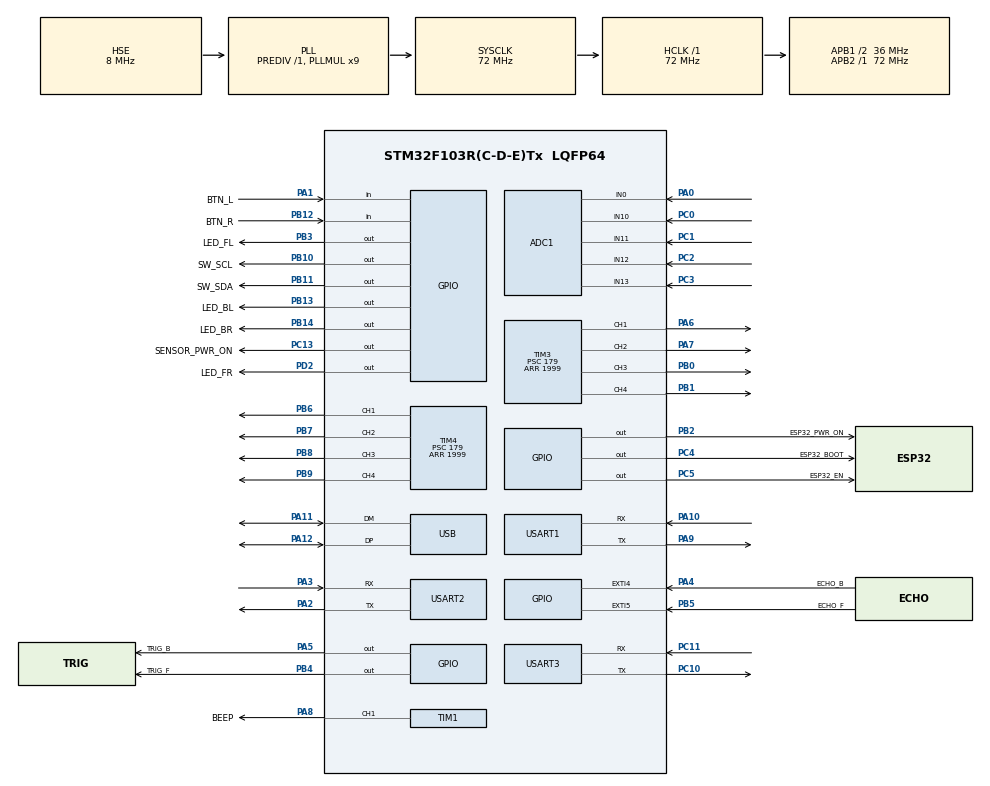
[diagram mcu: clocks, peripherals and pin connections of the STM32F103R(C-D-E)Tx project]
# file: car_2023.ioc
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ADC1.Channel-0\#ChannelRegularConversion=ADC_CHANNEL_10
ADC1.Channel-1\#ChannelRegularConversion=ADC_CHANNEL_11
ADC1.Channel-2\#ChannelRegularConversion=ADC_CHANNEL_12
ADC1.Channel-3\#ChannelRegularConversion=ADC_CHANNEL_13
ADC1.Channel-4\#ChannelRegularConversion=ADC_CHANNEL_0
ADC1.NbrOfConversion=5
ADC1.NbrOfConversionFlag=1
ADC1.Rank-0\#ChannelRegularConversion=1
ADC1.Rank-1\#ChannelRegularConversion=2
ADC1.Rank-2\#ChannelRegularConversion=3
ADC1.Rank-3\#ChannelRegularConversion=4
ADC1.Rank-4\#ChannelRegularConversion=5
ADC1.SamplingTime-0\#ChannelRegularConversion=ADC_SAMPLETIME_7CYCLES_5
ADC1.SamplingTime-1\#ChannelRegularConversion=ADC_SAMPLETIME_7CYCLES_5
ADC1.SamplingTime-2\#ChannelRegularConversion=ADC_SAMPLETIME_7CYCLES_5
ADC1.SamplingTime-3\#ChannelRegularConversion=ADC_SAMPLETIME_7CYCLES_5
ADC1.SamplingTime-4\#ChannelRegularConversion=ADC_SAMPLETIME_7CYCLES_5
ADC1.master=1
Dma.ADC1.4.Direction=DMA_PERIPH_TO_MEMORY
Dma.ADC1.4.Instance=DMA1_Channel1
Dma.ADC1.4.MemDataAlignment=DMA_MDATAALIGN_HALFWORD
Dma.ADC1.4.MemInc=DMA_MINC_ENABLE
Dma.ADC1.4.Mode=DMA_NORMAL
Dma.ADC1.4.PeriphDataAlignment=DMA_PDATAALIGN_HALFWORD
Dma.ADC1.4.PeriphInc=DMA_PINC_DISABLE
Dma.ADC1.4.Priority=DMA_PRIORITY_LOW
Dma.Request0=USART2_RX
Dma.Request1=USART2_TX
Dma.Request2=USART3_RX
Dma.Request3=USART3_TX
Dma.Request4=ADC1
Dma.USART2_RX.0.Direction=DMA_PERIPH_TO_MEMORY
Dma.USART2_RX.0.Instance=DMA1_Channel6
Dma.USART2_RX.0.MemDataAlignment=DMA_MDATAALIGN_BYTE
Dma.USART2_RX.0.MemInc=DMA_MINC_ENABLE
Dma.USART2_RX.0.Mode=DMA_NORMAL
Dma.USART2_RX.0.PeriphDataAlignment=DMA_PDATAALIGN_BYTE
Dma.USART2_RX.0.PeriphInc=DMA_PINC_DISABLE
Dma.USART2_RX.0.Priority=DMA_PRIORITY_LOW
Dma.USART2_TX.1.Direction=DMA_MEMORY_TO_PERIPH
Dma.USART2_TX.1.Instance=DMA1_Channel7
Dma.USART2_TX.1.MemDataAlignment=DMA_MDATAALIGN_BYTE
Dma.USART2_TX.1.MemInc=DMA_MINC_ENABLE
Dma.USART2_TX.1.Mode=DMA_NORMAL
Dma.USART2_TX.1.PeriphDataAlignment=DMA_PDATAALIGN_BYTE
Dma.USART2_TX.1.PeriphInc=DMA_PINC_DISABLE
Dma.USART2_TX.1.Priority=DMA_PRIORITY_LOW
Dma.USART3_RX.2.Direction=DMA_PERIPH_TO_MEMORY
Dma.USART3_RX.2.Instance=DMA1_Channel3
Dma.USART3_RX.2.MemDataAlignment=DMA_MDATAALIGN_BYTE
Dma.USART3_RX.2.MemInc=DMA_MINC_ENABLE
Dma.USART3_RX.2.Mode=DMA_NORMAL
Dma.USART3_RX.2.PeriphDataAlignment=DMA_PDATAALIGN_BYTE
Dma.USART3_RX.2.PeriphInc=DMA_PINC_DISABLE
Dma.USART3_RX.2.Priority=DMA_PRIORITY_LOW
Dma.USART3_TX.3.Direction=DMA_MEMORY_TO_PERIPH
Dma.USART3_TX.3.Instance=DMA1_Channel2
Dma.USART3_TX.3.MemDataAlignment=DMA_MDATAALIGN_BYTE
Dma.USART3_TX.3.MemInc=DMA_MINC_ENABLE
Dma.USART3_TX.3.Mode=DMA_NORMAL
Dma.USART3_TX.3.PeriphDataAlignment=DMA_PDATAALIGN_BYTE
Dma.USART3_TX.3.PeriphInc=DMA_PINC_DISABLE
Dma.USART3_TX.3.Priority=DMA_PRIORITY_LOW
Mcu.Family=STM32F1
Mcu.Name=STM32F103R(C-D-E)Tx
Mcu.Package=LQFP64
NVIC.ADC1_2_IRQn=true\:3\:0\:true\:false\:true\:true\:true\:true
NVIC.DMA1_Channel1_IRQn=true\:0\:0\:false\:false\:true\:false\:true\:true
NVIC.DMA1_Channel2_IRQn=true\:0\:0\:false\:false\:true\:false\:true\:true
NVIC.DMA1_Channel3_IRQn=true\:0\:0\:false\:false\:true\:false\:true\:true
NVIC.DMA1_Channel6_IRQn=true\:0\:0\:false\:false\:true\:false\:true\:true
NVIC.DMA1_Channel7_IRQn=true\:0\:0\:false\:false\:true\:false\:true\:true
NVIC.EXTI4_IRQn=true\:5\:0\:true\:false\:true\:true\:true\:true
NVIC.EXTI9_5_IRQn=true\:5\:0\:true\:false\:true\:true\:true\:true
NVIC.PriorityGroup=NVIC_PRIORITYGROUP_4
NVIC.TIM2_IRQn=true\:1\:0\:true\:false\:true\:true\:true\:true
NVIC.TIM6_IRQn=true\:4\:0\:true\:false\:true\:true\:true\:true
NVIC.TIM7_IRQn=true\:15\:0\:true\:false\:true\:true\:true\:true
NVIC.USART1_IRQn=true\:7\:0\:true\:false\:true\:true\:true\:true
NVIC.USART2_IRQn=true\:7\:0\:true\:false\:true\:true\:true\:true
NVIC.USART3_IRQn=true\:7\:0\:true\:false\:true\:true\:true\:true
NVIC.USB_LP_CAN1_RX0_IRQn=true\:0\:0\:false\:false\:true\:false\:true\:true
PA0-WKUP.Signal=ADCx_IN0
PA1.GPIO_Label=BTN_L
PA1.Signal=GPIO_Input
PA10.Mode=Asynchronous
PA10.Signal=USART1_RX
PA11.Mode=Device
PA11.Signal=USB_DM
PA12.Mode=Device
PA12.Signal=USB_DP
PA13.Mode=Serial_Wire
PA13.Signal=SYS_JTMS-SWDIO
PA14.Mode=Serial_Wire
PA14.Signal=SYS_JTCK-SWCLK
PA2.Mode=Asynchronous
PA2.Signal=USART2_TX
PA3.Mode=Asynchronous
PA3.Signal=USART2_RX
PA4.GPIO_Label=ECHO_B
PA4.Signal=GPXTI4
PA5.GPIO_Label=TRIG_B
PA5.Signal=GPIO_Output
PA6.Signal=S_TIM3_CH1
PA7.Signal=S_TIM3_CH2
PA8.GPIO_Label=BEEP
PA8.Signal=S_TIM1_CH1
PA9.Mode=Asynchronous
PA9.Signal=USART1_TX
PB0.Signal=S_TIM3_CH3
PB1.Signal=S_TIM3_CH4
PB10.GPIO_Label=SW_SCL
PB10.GPIO_ModeDefaultOutputPP=GPIO_MODE_OUTPUT_OD
PB10.GPIO_PuPd=GPIO_NOPULL
PB10.GPIO_Speed=GPIO_SPEED_FREQ_HIGH
PB10.Signal=GPIO_Output
PB11.GPIO_Label=SW_SDA
PB11.GPIO_ModeDefaultOutputPP=GPIO_MODE_OUTPUT_OD
PB11.GPIO_PuPd=GPIO_NOPULL
PB11.GPIO_Speed=GPIO_SPEED_FREQ_HIGH
PB11.Signal=GPIO_Output
PB12.GPIO_Label=BTN_R
PB12.Signal=GPIO_Input
PB13.GPIO_Label=LED_BL
PB13.Signal=GPIO_Output
PB14.GPIO_Label=LED_BR
PB14.Signal=GPIO_Output
PB2.GPIO_Label=ESP32_PWR_ON
PB2.PinState=GPIO_PIN_SET
PB2.Signal=GPIO_Output
PB3.GPIO_Label=LED_FL
PB3.Signal=GPIO_Output
PB4.GPIO_Label=TRIG_F
PB4.Signal=GPIO_Output
PB5.GPIO_Label=ECHO_F
PB5.Signal=GPXTI5
PB6.Signal=S_TIM4_CH1
PB7.Signal=S_TIM4_CH2
PB8.Signal=S_TIM4_CH3
PB9.Signal=S_TIM4_CH4
PC0.Signal=ADCx_IN10
PC1.Signal=ADCx_IN11
PC10.Mode=Asynchronous
PC10.Signal=USART3_TX
PC11.Mode=Asynchronous
PC11.Signal=USART3_RX
PC13-TAMPER-RTC.GPIO_Label=SENSOR_PWR_ON
PC13-TAMPER-RTC.Signal=GPIO_Output
PC14-OSC32_IN.Mode=LSE-External-Oscillator
PC14-OSC32_IN.Signal=RCC_OSC32_IN
PC15-OSC32_OUT.Mode=LSE-External-Oscillator
PC15-OSC32_OUT.Signal=RCC_OSC32_OUT
PC2.Signal=ADCx_IN12
PC3.Signal=ADCx_IN13
PC4.GPIO_Label=ESP32_BOOT
PC4.Signal=GPIO_Output
PC5.GPIO_Label=ESP32_EN
PC5.Signal=GPIO_Output
PD0-OSC_IN.Mode=HSE-External-Oscillator
PD0-OSC_IN.Signal=RCC_OSC_IN
PD1-OSC_OUT.Mode=HSE-External-Oscillator
PD1-OSC_OUT.Signal=RCC_OSC_OUT
PD2.GPIO_Label=LED_FR
PD2.Signal=GPIO_Output
ProjectManager.HeapSize=0x400
ProjectManager.StackSize=0x400
ProjectManager.TargetToolchain=STM32CubeIDE
RCC.ADCPresc=RCC_ADCPCLK2_DIV6
RCC.AHBFreq_Value=72000000
RCC.APB1CLKDivider=RCC_HCLK_DIV2
RCC.APB1Freq_Value=36000000
RCC.APB1TimFreq_Value=72000000
RCC.APB2Freq_Value=72000000
RCC.APB2TimFreq_Value=72000000
RCC.HCLKFreq_Value=72000000
RCC.PLLMUL=RCC_PLL_MUL9
RCC.SYSCLKFreq_VALUE=72000000
RCC.SYSCLKSource=RCC_SYSCLKSOURCE_PLLCLK
RCC.USBFreq_Value=48000000
RCC.USBPrescaler=RCC_USBCLKSOURCE_PLL_DIV1_5
SH.ADCx_IN0.0=ADC1_IN0,IN0
SH.ADCx_IN10.0=ADC1_IN10,IN10
SH.ADCx_IN11.0=ADC1_IN11,IN11
SH.ADCx_IN12.0=ADC1_IN12,IN12
SH.ADCx_IN13.0=ADC1_IN13,IN13
SH.S_TIM1_CH1.0=TIM1_CH1,PWM Generation1 CH1
SH.S_TIM3_CH1.0=TIM3_CH1,PWM Generation1 CH1
SH.S_TIM3_CH2.0=TIM3_CH2,PWM Generation2 CH2
SH.S_TIM3_CH3.0=TIM3_CH3,PWM Generation3 CH3
SH.S_TIM3_CH4.0=TIM3_CH4,PWM Generation4 CH4
SH.S_TIM4_CH1.0=TIM4_CH1,PWM Generation1 CH1
SH.S_TIM4_CH2.0=TIM4_CH2,PWM Generation2 CH2
SH.S_TIM4_CH3.0=TIM4_CH3,PWM Generation3 CH3
SH.S_TIM4_CH4.0=TIM4_CH4,PWM Generation4 CH4
TIM1.Channel-PWM\ Generation1\ CH1=TIM_CHANNEL_1
TIM1.Period=999
TIM1.Prescaler=71
TIM2.AutoReloadPreload=TIM_AUTORELOAD_PRELOAD_ENABLE
TIM2.Period=4999
TIM2.Prescaler=71
TIM3.Channel-PWM\ Generation1\ CH1=TIM_CHANNEL_1
TIM3.Channel-PWM\ Generation2\ CH2=TIM_CHANNEL_2
TIM3.Channel-PWM\ Generation3\ CH3=TIM_CHANNEL_3
TIM3.Channel-PWM\ Generation4\ CH4=TIM_CHANNEL_4
TIM3.Period=1999
TIM3.Prescaler=179
TIM4.Channel-PWM\ Generation1\ CH1=TIM_CHANNEL_1
TIM4.Channel-PWM\ Generation2\ CH2=TIM_CHANNEL_2
TIM4.Channel-PWM\ Generation3\ CH3=TIM_CHANNEL_3
TIM4.Channel-PWM\ Generation4\ CH4=TIM_CHANNEL_4
TIM4.Period=1999
TIM4.Prescaler=179
TIM6.Period=999
TIM6.Prescaler=719
TIM7.Period=9999
TIM7.Prescaler=3599
TIM8.Prescaler=8
USART1.VirtualMode=VM_ASYNC
USART2.VirtualMode=VM_ASYNC
USART3.VirtualMode=VM_ASYNC
USB_DEVICE.CLASS_NAME_FS=CDC
USB_DEVICE.VirtualMode=Cdc
USB_DEVICE.VirtualModeFS=Cdc_FS
VP_TIM1_VS_ClockSourceINT.Mode=Internal
VP_TIM2_VS_ClockSourceINT.Mode=Internal
VP_TIM3_VS_ClockSourceINT.Mode=Internal
VP_TIM4_VS_ClockSourceINT.Mode=Internal
VP_TIM6_VS_ClockSourceINT.Mode=Enable_Timer
VP_TIM7_VS_ClockSourceINT.Mode=Enable_Timer
VP_TIM8_VS_ClockSourceINT.Mode=Internal
VP_USB_DEVICE_VS_USB_DEVICE_CDC_FS.Mode=CDC_FS
board=custom

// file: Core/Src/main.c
/* USER CODE BEGIN Header */
/**
  ******************************************************************************
  * @file           : main.c
  * @brief          : Main program body
  ******************************************************************************
  * @attention
  *
  * Copyright (c) 2023 STMicroelectronics.
  * All rights reserved.
  *
  * This software is licensed under terms that can be found in the LICENSE file
  * in the root directory of this software component.
  * If no LICENSE file comes with this software, it is provided AS-IS.
  *
  ******************************************************************************
  */
/* USER CODE END Header */
#include "main.h"
#include "adc.h"
#include "dma.h"
#include "tim.h"
#include "usart.h"
#include "usb_device.h"
#include "gpio.h"

/* USER CODE BEGIN Includes */
#include "common.h"
#include "motor_drive.h"
#include "../Usr/MPU6050.h"
#include "../Usr/angleCtrl.h"
#include "../Usr/motorCtrl.h"
/* USER CODE END Includes */

void SystemClock_Config(void);

int main(void)
{

  /* MCU Configuration--------------------------------------------------------*/

  /* Reset of all peripherals, Initializes the Flash interface and the Systick. */
  HAL_Init();

  /* Configure the system clock */
  SystemClock_Config();

  /* Initialize all configured peripherals */
  MX_GPIO_Init();
  MX_DMA_Init();
  MX_ADC1_Init();
  MX_TIM1_Init();
  MX_TIM3_Init();
  MX_TIM4_Init();
  MX_USART1_UART_Init();
  MX_USART2_UART_Init();
  MX_USART3_UART_Init();
  MX_USB_DEVICE_Init();
  MX_TIM6_Init();
  MX_TIM7_Init();
  MX_TIM8_Init();
  MX_TIM2_Init();
  /* USER CODE BEGIN 2 */
    System_Init();

    MPU6050_Init();
    MPU6050_Calibration();
  /* USER CODE END 2 */

  /* Infinite loop */
  /* USER CODE BEGIN WHILE */
    while (1) {
        UserTasks();
//        TURN_ANGLE(90, 5, 0);
//        CarMotoCtrl(0,0);
//        HAL_Delay(1000000);

    /* USER CODE END WHILE */

    }
}

void SystemClock_Config(void)
{
  RCC_OscInitTypeDef RCC_OscInitStruct = {0};
  RCC_ClkInitTypeDef RCC_ClkInitStruct = {0};
  RCC_PeriphCLKInitTypeDef PeriphClkInit = {0};

  /** Initializes the RCC Oscillators according to the specified parameters
  * in the RCC_OscInitTypeDef structure.
  */
  RCC_OscInitStruct.OscillatorType = RCC_OSCILLATORTYPE_HSE;
  RCC_OscInitStruct.HSEState = RCC_HSE_ON;
  RCC_OscInitStruct.HSEPredivValue = RCC_HSE_PREDIV_DIV1;
  RCC_OscInitStruct.HSIState = RCC_HSI_ON;
  RCC_OscInitStruct.PLL.PLLState = RCC_PLL_ON;
  RCC_OscInitStruct.PLL.PLLSource = RCC_PLLSOURCE_HSE;
  RCC_OscInitStruct.PLL.PLLMUL = RCC_PLL_MUL9;
  if (HAL_RCC_OscConfig(&RCC_OscInitStruct) != HAL_OK)
  {
    Error_Handler();
  }

  /** Initializes the CPU, AHB and APB buses clocks
  */
  RCC_ClkInitStruct.ClockType = RCC_CLOCKTYPE_HCLK|RCC_CLOCKTYPE_SYSCLK
                              |RCC_CLOCKTYPE_PCLK1|RCC_CLOCKTYPE_PCLK2;
  RCC_ClkInitStruct.SYSCLKSource = RCC_SYSCLKSOURCE_PLLCLK;
  RCC_ClkInitStruct.AHBCLKDivider = RCC_SYSCLK_DIV1;
  RCC_ClkInitStruct.APB1CLKDivider = RCC_HCLK_DIV2;
  RCC_ClkInitStruct.APB2CLKDivider = RCC_HCLK_DIV1;

  if (HAL_RCC_ClockConfig(&RCC_ClkInitStruct, FLASH_LATENCY_2) != HAL_OK)
  {
    Error_Handler();
  }
  PeriphClkInit.PeriphClockSelection = RCC_PERIPHCLK_ADC|RCC_PERIPHCLK_USB;
  PeriphClkInit.AdcClockSelection = RCC_ADCPCLK2_DIV6;
  PeriphClkInit.UsbClockSelection = RCC_USBCLKSOURCE_PLL_DIV1_5;
  if (HAL_RCCEx_PeriphCLKConfig(&PeriphClkInit) != HAL_OK)
  {
    Error_Handler();
  }
}

void Error_Handler(void)
{
    __disable_irq();
    while (1) {
    }
}
